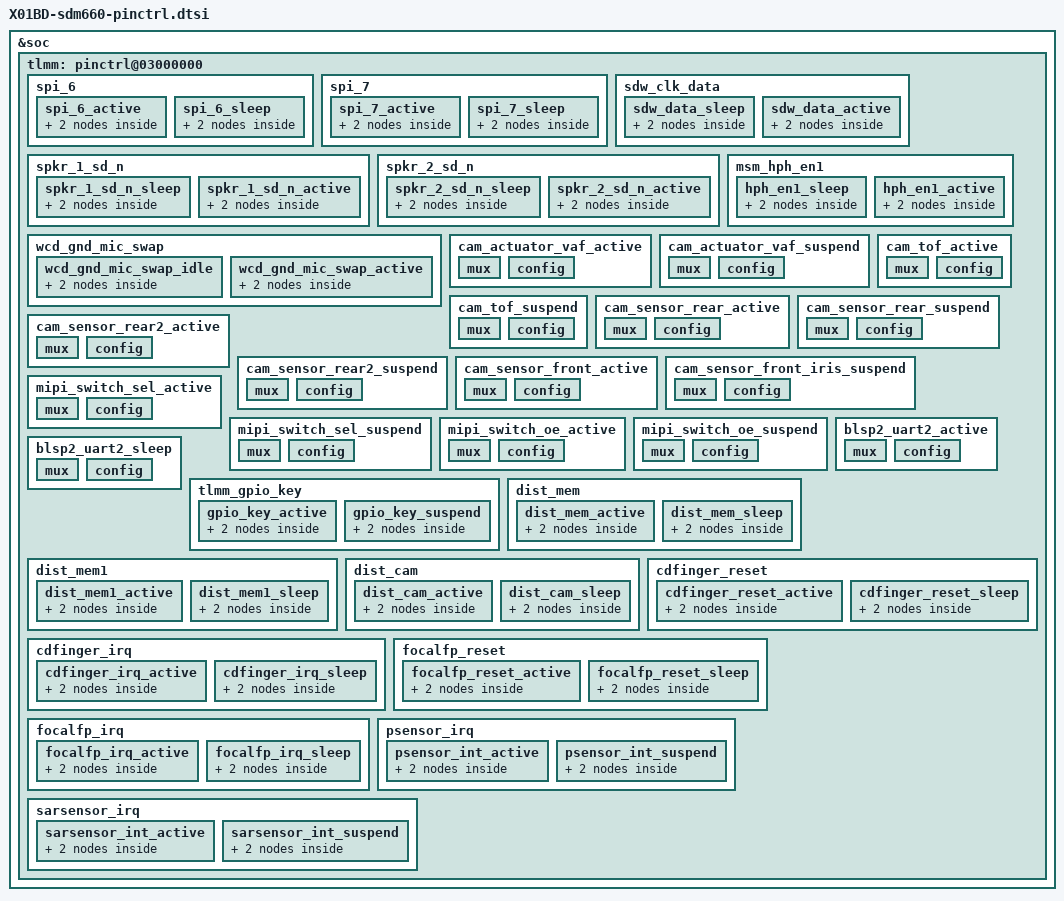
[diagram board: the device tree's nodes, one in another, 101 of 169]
/* Copyright (c) 2017, The Linux Foundation. All rights reserved.
 *
 * This program is free software; you can redistribute it and/or modify
 * it under the terms of the GNU General Public License version 2 and
 * only version 2 as published by the Free Software Foundation.
 *
 * This program is distributed in the hope that it will be useful,
 * but WITHOUT ANY WARRANTY; without even the implied warranty of
 * MERCHANTABILITY or FITNESS FOR A PARTICULAR PURPOSE.  See the
 * GNU General Public License for more details.
 */

&soc {
	tlmm: pinctrl@03000000 {

		spi_6 {
			spi_6_active: spi_6_active {
				mux {
					pins = "gpio49", "gpio107",
							"gpio22", "gpio23";
					function = "blsp_spi6";
				};

				config {
					pins = "gpio49", "gpio107",
							"gpio22", "gpio23";
					drive-strength = <6>;
					bias-disable;
				};
			};

			spi_6_sleep: spi_6_sleep {
				mux {
					pins = "gpio49", "gpio107",
							"gpio22", "gpio23";
					function = "blsp_spi6";
				};

				config {
					pins = "gpio49", "gpio107",
							"gpio22", "gpio23";
					drive-strength = <6>;
					bias-disable;
				};
			};
		};

		spi_7 {
			spi_7_active: spi_7_active {
				mux {
					pins = "gpio24", "gpio107",
							"gpio26", "gpio27";
					function = "blsp_spi7";
				};

				config {
					pins = "gpio24", "gpio107",
							"gpio26", "gpio27";
					drive-strength = <6>;
					bias-disable;
				};
			};

			spi_7_sleep: spi_7_sleep {
				mux {
					pins = "gpio24", "gpio107",
							"gpio26", "gpio27";
					function = "blsp_spi7";
				};

				config {
					pins = "gpio24", "gpio107",
							"gpio26", "gpio27";
					drive-strength = <6>;
					bias-disable;
				};
			};
		};

		sdw_clk_data {
			sdw_data_sleep: sdw_data_sleep {
				mux {
					pins = "gpio107";
					function = "sndwire_data";
				};

				config {
					pins = "gpio107";
					drive-strength = <4>;
					bias-bus-hold;
				};
			};

			sdw_data_active: sdw_data_active {
				mux {
					pins = "gpio107";
					function = "sndwire_data";
				};

				config {
					pins = "gpio107";
					drive-strength = <4>;
					bias-bus-hold;
				};
			};
		};

		spkr_1_sd_n {
			spkr_1_sd_n_sleep: spkr_1_sd_n_sleep {
				mux {
					pins = "gpio70";
					function = "gpio";
				};

				config {
					pins = "gpio70";
					drive-strength = <2>;   /* 2 mA */
					bias-pull-down;
					input-enable;
				};
			};

			spkr_1_sd_n_active: spkr_1_sd_n_active {
				mux {
					pins = "gpio70";
					function = "gpio";
				};

				config {
					pins = "gpio70";
					drive-strength = <16>;   /* 16 mA */
					bias-disable;
					output-high;
				};
			};
		};

		spkr_2_sd_n {
			spkr_2_sd_n_sleep: spkr_2_sd_n_sleep {
				mux {
					pins = "gpio107";
					function = "gpio";
				};

				config {
					pins = "gpio107";
					drive-strength = <2>;   /* 2 mA */
					bias-pull-down;
					input-enable;
				};
			};

			spkr_2_sd_n_active: spkr_2_sd_n_active {
				mux {
					pins = "gpio107";
					function = "gpio";
				};

				config {
					pins = "gpio107";
					drive-strength = <16>;   /* 16 mA */
					bias-disable;
					output-high;
				};
			};
		};

		wcd_gnd_mic_swap {
			wcd_gnd_mic_swap_idle: wcd_gnd_mic_swap_idle {
				mux {
					pins = "gpio999";
					function = "gpio";
				};
				config {
					pins = "gpio999";
					drive-strength = <2>;
					bias-pull-down;
					output-low;
				};
			};

			wcd_gnd_mic_swap_active: wcd_gnd_mic_swap_active {
				mux {
					pins = "gpio999";
					function = "gpio";
				};
				config {
					pins = "gpio999";
					drive-strength = <2>;
					bias-disable;
					output-high;
				};
			};
		};

		msm_hph_en1 {
			hph_en1_sleep: hph_en1_sleep {
				mux {
					pins = "gpio107";
					function = "gpio";
				};

				config {
					pins = "gpio107";
					output-low;
				};
			};

			hph_en1_active: hph_en1_active {
				mux {
					pins = "gpio107";
					function = "gpio";
				};

				config {
					pins = "gpio107";
					output-high;
				};
			};
		};

		cam_actuator_vaf_active: cam_actuator_vaf_active {
			/* ACTUATOR POWER */
			mux {
				pins = "gpio107";
				function = "gpio";
			};

			config {
				pins = "gpio107";
				bias-disable; /* No PULL */
				drive-strength = <2>; /* 2 MA */
			};
		};

		cam_actuator_vaf_suspend: cam_actuator_vaf_suspend {
			/* ACTUATOR POWER */
			mux {
				pins = "gpio107";
				function = "gpio";
			};

			config {
				pins = "gpio107";
				bias-pull-down; /* PULL DOWN */
				drive-strength = <2>; /* 2 MA */
			};
		};

		cam_tof_active: cam_tof_active {
			/* LASER */
			mux {
				pins = "gpio107", "gpio42";
				function = "gpio";
			};

			config {
				pins = "gpio107", "gpio42";
				bias-pull-up;
				drive-strength = <2>; /* 2 MA */
			};
		};

		cam_tof_suspend: cam_tof_suspend {
			/* LASER */
			mux {
				pins = "gpio107", "gpio42";
				function = "gpio";
			};

			config {
				pins = "gpio107", "gpio42";
				bias-pull-down; /* PULL DOWN */
				drive-strength = <2>; /* 2 MA */
			};
		};

		cam_sensor_rear_active: cam_sensor_rear_active {
			/* RESET, STANDBY */
			mux {
				pins = "gpio46";
				function = "gpio";
			};

			config {
				pins = "gpio46";
				bias-disable; /* No PULL */
				drive-strength = <2>; /* 2 MA */
			};
		};

		cam_sensor_rear_suspend: cam_sensor_rear_suspend {
			/* RESET, STANDBY */
			mux {
				pins = "gpio46";
				function = "gpio";
			};

			config {
				pins = "gpio46";
				bias-disable; /* No PULL */
				drive-strength = <2>; /* 2 MA */
			};
		};
		cam_sensor_rear2_active: cam_sensor_rear2_active {
			/* RESET */
			mux {
				pins = "gpio48";
				function = "gpio";
			};

			config {
				pins = "gpio48";
				bias-disable; /* No PULL */
				drive-strength = <2>; /* 2 MA */
			};
		};

		cam_sensor_rear2_suspend: cam_sensor_rear2_suspend {
			/* RESET */
			mux {
				pins = "gpio48";
				function = "gpio";
			};
			config {
				pins = "gpio48";
				bias-disable; /* No PULL */
				drive-strength = <2>; /* 2 MA */
			};
		};
		cam_sensor_front_active: cam_sensor_front_active {
			/* RESET  VANA*/
			mux {
				pins = "gpio47";
				function = "gpio";
			};

			config {
				pins = "gpio47";
				bias-disable; /* No PULL */
				drive-strength = <2>; /* 2 MA */
			};
		};
		cam_sensor_front_iris_suspend: cam_sensor_front_iris_suspend {
			/* RESET */
			mux {
				pins = "gpio52";
				function = "gpio";
			};

			config {
				pins = "gpio52";
				bias-disable; /* No PULL */
				drive-strength = <2>; /* 2 MA */
			};
		};

		mipi_switch_sel_active: mipi_switch_sel_active {
			/* RESET */
			mux {
				pins = "gpio74";
				function = "gpio";
			};

			config {
				pins = "gpio74";
				bias-disable; /* No PULL */
				drive-strength = <2>; /* 2 MA */
			};
		};
		mipi_switch_sel_suspend: mipi_switch_sel_suspend {
			/* RESET */
			mux {
				pins = "gpio74";
				function = "gpio";
			};

			config {
				pins = "gpio74";
				bias-disable; /* No PULL */
				drive-strength = <2>; /* 2 MA */
			};
		};

		mipi_switch_oe_active: mipi_switch_oe_active {
			/* RESET */
			mux {
				pins = "gpio75";
				function = "gpio";
			};

			config {
				pins = "gpio75";
				bias-disable; /* No PULL */
				drive-strength = <2>; /* 2 MA */
			};
		};
		mipi_switch_oe_suspend: mipi_switch_oe_suspend {
			/* RESET */
			mux {
				pins = "gpio75";
				function = "gpio";
			};

			config {
				pins = "gpio75";
				bias-disable; /* No PULL */
				drive-strength = <2>; /* 2 MA */
			};
		};

		blsp2_uart2_active: blsp2_uart2_active {
			mux {
				pins = "gpio24", "gpio107";
				function = "blsp_uart6_a";
			};

			config {
				pins = "gpio24", "gpio107";
				drive-strength = <2>;
				bias-disable;
			};
		};

		blsp2_uart2_sleep: blsp2_uart2_sleep {
			mux {
				pins = "gpio24", "gpio107";
				function = "gpio";
			};

			config {
				pins = "gpio24", "gpio107";
				drive-strength = <2>;
				bias-disable;
			};
		};

		tlmm_gpio_key {
			gpio_key_active: gpio_key_active {
				mux {
					pins = "gpio43", "gpio44";
					function = "gpio";
				};

				config {
					pins = "gpio43", "gpio44";
					drive-strength = <2>;
					bias-pull-up;
				};
			};

			gpio_key_suspend: gpio_key_suspend {
				mux {
					pins = "gpio43", "gpio44";
					function = "gpio";
				};

				config {
					pins = "gpio43", "gpio44";
					drive-strength = <2>;
					bias-pull-up;
				};
			};
		};

		dist_mem {
			dist_mem_active: dist_mem_active {
				mux {
					pins = "gpio63";
					function = "gpio";
				};

				config {
					pins = "gpio63";
					drive-strength = <2>;
					bias-pull-up;
					input-enable;
				};
			};

			dist_mem_sleep: dist_mem_sleep {
				mux {
					pins = "gpio63";
					function = "gpio";
				};

				config {
					pins = "gpio63";
					drive-strength = <2>;
					bias-pull-up;
					input-enable;
				};
			};
		};

		dist_mem1 {
			dist_mem1_active: dist_mem1_active {
				mux {
					pins = "gpio64";
					function = "gpio";
				};

				config {
					pins = "gpio64";
					drive-strength = <2>;
					bias-pull-up;
					input-enable;
				};
			};

			dist_mem1_sleep: dist_mem1_sleep {
				mux {
					pins = "gpio64";
					function = "gpio";
				};

				config {
					pins = "gpio64";
					drive-strength = <2>;
					bias-pull-up;
					input-enable;
				};
			};
		};

		dist_cam {
			dist_cam_active: dist_cam_active {
				mux {
					pins = "gpio21";
					function = "gpio";
				};

				config {
					pins = "gpio21";
					drive-strength = <2>;
					bias-pull-up;
					input-enable;
				};
			};

			dist_cam_sleep: dist_cam_sleep {
				mux {
					pins = "gpio21";
					function = "gpio";
				};

				config {
					pins = "gpio21";
					drive-strength = <2>;
					bias-pull-up;
					input-enable;
				};
			};
		};

		cdfinger_reset {
			cdfinger_reset_active: cdfinger_reset_active {
				mux {
					pins = "gpio20";
					function = "gpio";
				};

				config {
					pins = "gpio20";
					drive-strength = <2>;
					bias-pull-up;
				};
			};

			cdfinger_reset_sleep: cdfinger_reset_sleep {
				mux {
					pins = "gpio20";
					function = "gpio";
				};

				config {
					pins = "gpio20";
					drive-strength = <2>;
					bias-pull-up;
				};
			};
		};

		cdfinger_irq {
			cdfinger_irq_active: cdfinger_irq_active {
				mux {
					pins = "gpio72";
					function = "gpio";
				};

				config {
					pins = "gpio72";
					drive-strength = <2>;
					bias-disable;
				};
			};

			cdfinger_irq_sleep: cdfinger_irq_sleep {
				mux {
					pins = "gpio72";
					function = "gpio";
				};

				config {
					pins = "gpio72";
					drive-strength = <2>;
					bias-disable;
				};
			};
		};

		focalfp_reset {
			focalfp_reset_active: focalfp_reset_active {
				mux {
					pins = "gpio20";
					function = "gpio";
				};

				config {
					pins = "gpio20";
					drive-strength = <2>;
					bias-pull-up;
				};
			};

			focalfp_reset_sleep: focalfp_reset_sleep {
				mux {
					pins = "gpio20";
					function = "gpio";
				};

				config {
					pins = "gpio20";
					drive-strength = <2>;
					bias-pull-up;
				};
			};
		};

		focalfp_irq {
			focalfp_irq_active: focalfp_irq_active {
				mux {
					pins = "gpio72";
					function = "gpio";
				};

				config {
					pins = "gpio72";
					drive-strength = <2>;
					bias-disable;
				};
			};

			focalfp_irq_sleep: focalfp_irq_sleep {
				mux {
					pins = "gpio72";
					function = "gpio";
				};

				config {
					pins = "gpio72";
					drive-strength = <2>;
					bias-disable;
				};
			};
		};

		psensor_irq {
			psensor_int_active: psensor_int_active {
				mux {
					pins = "gpio45";
					function = "gpio";
				};

				config {
					pins = "gpio45";
					drive-strength = <2>;
					bias-pull-up;
					input-enable;
				};
			};

			psensor_int_suspend: psensor_int_suspend {
				mux {
					pins = "gpio45";
					function = "gpio";
				};

				config {
					pins = "gpio45";
					drive-strength = <2>;
					bias-pull-up;
					input-enable;
				};
			};
		};

		sarsensor_irq {
			sarsensor_int_active: sarsensor_int_active {
				mux {
					pins = "gpio77";
					function = "gpio";
				};

				config {
					pins = "gpio77";
					drive-strength = <2>;
					bias-pull-up;
					input-enable;
				};
			};

			sarsensor_int_suspend: sarsensor_int_suspend {
				mux {
					pins = "gpio77";
					function = "gpio";
				};

				config {
					pins = "gpio77";
					drive-strength = <2>;
					bias-pull-up;
					input-enable;
				};
			};
		};
	};
};
